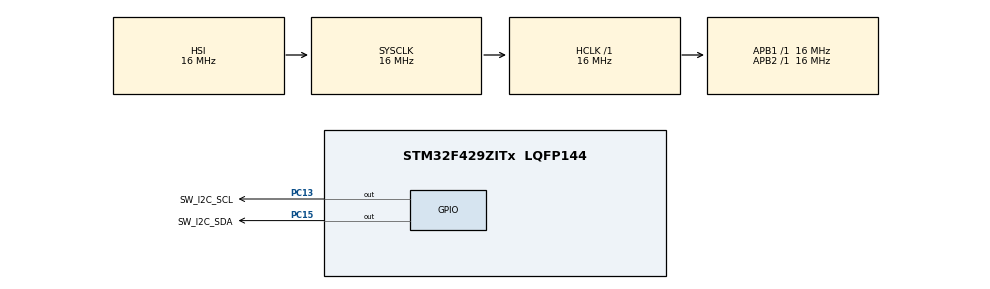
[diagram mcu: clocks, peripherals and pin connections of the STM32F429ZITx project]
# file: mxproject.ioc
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Mcu.Family=STM32F4
Mcu.Name=STM32F429ZITx
Mcu.Package=LQFP144
NVIC.PriorityGroup=NVIC_PRIORITYGROUP_4
PC13.GPIO_Label=SW_I2C_SCL
PC13.GPIO_ModeDefaultOutputPP=GPIO_MODE_OUTPUT_OD
PC13.GPIO_PuPd=GPIO_NOPULL
PC13.Signal=GPIO_Output
PC15/OSC32_OUT.GPIO_Label=SW_I2C_SDA
PC15/OSC32_OUT.GPIO_ModeDefaultOutputPP=GPIO_MODE_OUTPUT_OD
PC15/OSC32_OUT.GPIO_PuPd=GPIO_NOPULL
PC15/OSC32_OUT.Signal=GPIO_Output
ProjectManager.HeapSize=0x200
ProjectManager.StackSize=0x400
ProjectManager.TargetToolchain=Makefile
RCC.AHBFreq_Value=16000000
RCC.APB1Freq_Value=16000000
RCC.APB2Freq_Value=16000000
RCC.CortexFreq_Value=16000000
RCC.HSE_VALUE=25000000
RCC.HSI_VALUE=16000000
RCC.LSE_VALUE=32768
RCC.SYSCLKFreq_VALUE=16000000
RCC.VCOOutputFreq_Value=192000000
board=custom

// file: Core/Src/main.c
/* USER CODE BEGIN Header */
/**
 ******************************************************************************
 * @file           : main.c
 * @brief          : Main program body
 ******************************************************************************
 * @attention
 *
 * Copyright (c) 2025 STMicroelectronics.
 * All rights reserved.
 *
 * This software is licensed under terms that can be found in the LICENSE file
 * in the root directory of this software component.
 * If no LICENSE file comes with this software, it is provided AS-IS.
 *
 ******************************************************************************
 */
/* USER CODE END Header */
#include "main.h"

/* USER CODE BEGIN Includes */
#include <stdio.h>
#include <string.h>
#include <stdbool.h>
#include "stm32_sw_i2c.h"
#include "dwt_stm32_delay.h"
/* USER CODE END Includes */

void SystemClock_Config(void);
static void MX_GPIO_Init(void);

int main(void)
{

  /* MCU Configuration--------------------------------------------------------*/

  /* Reset of all peripherals, Initializes the Flash interface and the Systick. */
  HAL_Init();

  /* Configure the system clock */
  SystemClock_Config();

  /* USER CODE BEGIN SysInit */
  I2C_init();
  DWT_Delay_Init();
  /* USER CODE END SysInit */

  /* Initialize all configured peripherals */
  MX_GPIO_Init();
  /* USER CODE BEGIN 2 */
  uint8_t data[256];
  I2C_transmit(0x68 << 1, data, 2);
  /* USER CODE END 2 */

  /* Infinite loop */
  /* USER CODE BEGIN WHILE */
  // while (1) {
    /* USER CODE END WHILE */

    /* USER CODE BEGIN 3 */

  // }

  /* USER CODE END 3 */
}

void SystemClock_Config(void)
{
  RCC_OscInitTypeDef RCC_OscInitStruct = {0};
  RCC_ClkInitTypeDef RCC_ClkInitStruct = {0};

  /** Configure the main internal regulator output voltage
  */
  __HAL_RCC_PWR_CLK_ENABLE();
  __HAL_PWR_VOLTAGESCALING_CONFIG(PWR_REGULATOR_VOLTAGE_SCALE3);

  /** Initializes the RCC Oscillators according to the specified parameters
  * in the RCC_OscInitTypeDef structure.
  */
  RCC_OscInitStruct.OscillatorType = RCC_OSCILLATORTYPE_HSI;
  RCC_OscInitStruct.HSIState = RCC_HSI_ON;
  RCC_OscInitStruct.HSICalibrationValue = RCC_HSICALIBRATION_DEFAULT;
  RCC_OscInitStruct.PLL.PLLState = RCC_PLL_NONE;
  if (HAL_RCC_OscConfig(&RCC_OscInitStruct) != HAL_OK)
  {
    Error_Handler();
  }

  /** Initializes the CPU, AHB and APB buses clocks
  */
  RCC_ClkInitStruct.ClockType = RCC_CLOCKTYPE_HCLK|RCC_CLOCKTYPE_SYSCLK
                              |RCC_CLOCKTYPE_PCLK1|RCC_CLOCKTYPE_PCLK2;
  RCC_ClkInitStruct.SYSCLKSource = RCC_SYSCLKSOURCE_HSI;
  RCC_ClkInitStruct.AHBCLKDivider = RCC_SYSCLK_DIV1;
  RCC_ClkInitStruct.APB1CLKDivider = RCC_HCLK_DIV1;
  RCC_ClkInitStruct.APB2CLKDivider = RCC_HCLK_DIV1;

  if (HAL_RCC_ClockConfig(&RCC_ClkInitStruct, FLASH_LATENCY_0) != HAL_OK)
  {
    Error_Handler();
  }
}

static void MX_GPIO_Init(void)
{
  GPIO_InitTypeDef GPIO_InitStruct = {0};

  /* GPIO Ports Clock Enable */
  __HAL_RCC_GPIOC_CLK_ENABLE();

  /*Configure GPIO pin Output Level */
  HAL_GPIO_WritePin(GPIOC, SW_I2C_SCL_Pin|SW_I2C_SDA_Pin, GPIO_PIN_RESET);

  /*Configure GPIO pins : SW_I2C_SCL_Pin SW_I2C_SDA_Pin */
  GPIO_InitStruct.Pin = SW_I2C_SCL_Pin|SW_I2C_SDA_Pin;
  GPIO_InitStruct.Mode = GPIO_MODE_OUTPUT_OD;
  GPIO_InitStruct.Pull = GPIO_NOPULL;
  GPIO_InitStruct.Speed = GPIO_SPEED_FREQ_LOW;
  HAL_GPIO_Init(GPIOC, &GPIO_InitStruct);

}

void Error_Handler(void)
{
	__disable_irq();
	while (1) {
	}
}
